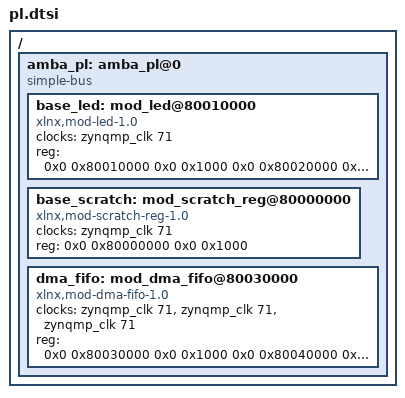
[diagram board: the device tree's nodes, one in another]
/*
 * CAUTION: This file is automatically generated by Xilinx.
 * Version: XSCT 2019.2.1
 * Today is: Wed Aug 19 15:07:07 2020
 */


/ {
	amba_pl: amba_pl@0 {
		#address-cells = <2>;
		#size-cells = <2>;
		compatible = "simple-bus";
		ranges ;
		base_led: mod_led@80010000 {
			/* This is a place holder node for a custom IP, user may need to update the entries */
			clock-names = "ACLK_0";
			clocks = <&zynqmp_clk 71>;
			compatible = "xlnx,mod-led-1.0";
			reg = <0x0 0x80010000 0x0 0x1000 0x0 0x80020000 0x0 0x1000>;
		};
		base_scratch: mod_scratch_reg@80000000 {
			/* This is a place holder node for a custom IP, user may need to update the entries */
			clock-names = "s_axi_aclk";
			clocks = <&zynqmp_clk 71>;
			compatible = "xlnx,mod-scratch-reg-1.0";
			reg = <0x0 0x80000000 0x0 0x1000>;
		};
		dma_fifo: mod_dma_fifo@80030000 {
			/* This is a place holder node for a custom IP, user may need to update the entries */
			clock-names = "m_axi_mm2s_aclk", "m_axi_s2mm_aclk", "s_axi_lite_aclk";
			clocks = <&zynqmp_clk 71>, <&zynqmp_clk 71>, <&zynqmp_clk 71>;
			compatible = "xlnx,mod-dma-fifo-1.0";
			reg = <0x0 0x80030000 0x0 0x1000 0x0 0x80040000 0x0 0x1000>;
		};
	};
};
